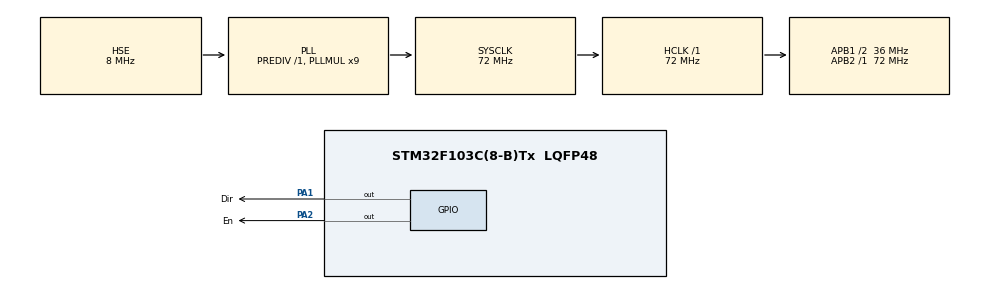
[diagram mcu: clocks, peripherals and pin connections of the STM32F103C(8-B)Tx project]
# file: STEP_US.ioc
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FREERTOS.Tasks01=defaultTask,0,128,StartDefaultTask,Default,NULL,Dynamic,NULL,NULL
Mcu.Family=STM32F1
Mcu.Name=STM32F103C(8-B)Tx
Mcu.Package=LQFP48
NVIC.PriorityGroup=NVIC_PRIORITYGROUP_4
PA1.GPIO_Label=Dir
PA1.Signal=GPIO_Output
PA13.Mode=Serial_Wire
PA13.Signal=SYS_JTMS-SWDIO
PA14.Mode=Serial_Wire
PA14.Signal=SYS_JTCK-SWCLK
PA2.GPIO_Label=En
PA2.Signal=GPIO_Output
PD0-OSC_IN.Mode=HSE-External-Oscillator
PD0-OSC_IN.Signal=RCC_OSC_IN
PD1-OSC_OUT.Mode=HSE-External-Oscillator
PD1-OSC_OUT.Signal=RCC_OSC_OUT
ProjectManager.HeapSize=0x200
ProjectManager.StackSize=0x400
ProjectManager.TargetToolchain=STM32CubeIDE
RCC.AHBFreq_Value=72000000
RCC.APB1CLKDivider=RCC_HCLK_DIV2
RCC.APB1Freq_Value=36000000
RCC.APB1TimFreq_Value=72000000
RCC.APB2Freq_Value=72000000
RCC.APB2TimFreq_Value=72000000
RCC.HCLKFreq_Value=72000000
RCC.PLLMUL=RCC_PLL_MUL9
RCC.PLLSourceVirtual=RCC_PLLSOURCE_HSE
RCC.SYSCLKFreq_VALUE=72000000
RCC.SYSCLKSource=RCC_SYSCLKSOURCE_PLLCLK
RCC.USBFreq_Value=72000000
TIM2.Prescaler=72-1
VP_FREERTOS_VS_CMSIS_V1.Mode=CMSIS_V1
VP_TIM2_VS_ClockSourceINT.Mode=Internal
board=custom

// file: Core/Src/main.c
/* USER CODE BEGIN Header */
/**
  ******************************************************************************
  * @file           : main.c
  * @brief          : Main program body
  ******************************************************************************
  * @attention
  *
  * Copyright (c) 2023 STMicroelectronics.
  * All rights reserved.
  *
  * This software is licensed under terms that can be found in the LICENSE file
  * in the root directory of this software component.
  * If no LICENSE file comes with this software, it is provided AS-IS.
  *
  ******************************************************************************
  */
/* USER CODE END Header */
#include "main.h"
#include "cmsis_os.h"

TIM_HandleTypeDef htim2;

osThreadId defaultTaskHandle;

void SystemClock_Config(void);
static void MX_GPIO_Init(void);
static void MX_TIM2_Init(void);
void StartDefaultTask(void const * argument);

/* USER CODE BEGIN 0 */
void Delayus(uint16_t us){
	__HAL_TIM_SET_COUNTER(&htim2,0);
		while(__HAL_TIM_GET_COUNTER(&htim2)<us);
}
/* USER CODE END 0 */

int main(void)
{

  /* MCU Configuration--------------------------------------------------------*/

  /* Reset of all peripherals, Initializes the Flash interface and the Systick. */
  HAL_Init();

  /* Configure the system clock */
  SystemClock_Config();

  /* Initialize all configured peripherals */
  MX_GPIO_Init();
  MX_TIM2_Init();

  /* Create the thread(s) */
  /* definition and creation of defaultTask */
  osThreadDef(defaultTask, StartDefaultTask, osPriorityNormal, 0, 128);
  defaultTaskHandle = osThreadCreate(osThread(defaultTask), NULL);

  /* Start scheduler */
  osKernelStart();

  /* We should never get here as control is now taken by the scheduler */
  /* Infinite loop */
  while (1)
  {

  }
}

void SystemClock_Config(void)
{
  RCC_OscInitTypeDef RCC_OscInitStruct = {0};
  RCC_ClkInitTypeDef RCC_ClkInitStruct = {0};

  /** Initializes the RCC Oscillators according to the specified parameters
  * in the RCC_OscInitTypeDef structure.
  */
  RCC_OscInitStruct.OscillatorType = RCC_OSCILLATORTYPE_HSE;
  RCC_OscInitStruct.HSEState = RCC_HSE_ON;
  RCC_OscInitStruct.HSEPredivValue = RCC_HSE_PREDIV_DIV1;
  RCC_OscInitStruct.HSIState = RCC_HSI_ON;
  RCC_OscInitStruct.PLL.PLLState = RCC_PLL_ON;
  RCC_OscInitStruct.PLL.PLLSource = RCC_PLLSOURCE_HSE;
  RCC_OscInitStruct.PLL.PLLMUL = RCC_PLL_MUL9;
  if (HAL_RCC_OscConfig(&RCC_OscInitStruct) != HAL_OK)
  {
    Error_Handler();
  }

  /** Initializes the CPU, AHB and APB buses clocks
  */
  RCC_ClkInitStruct.ClockType = RCC_CLOCKTYPE_HCLK|RCC_CLOCKTYPE_SYSCLK
                              |RCC_CLOCKTYPE_PCLK1|RCC_CLOCKTYPE_PCLK2;
  RCC_ClkInitStruct.SYSCLKSource = RCC_SYSCLKSOURCE_PLLCLK;
  RCC_ClkInitStruct.AHBCLKDivider = RCC_SYSCLK_DIV1;
  RCC_ClkInitStruct.APB1CLKDivider = RCC_HCLK_DIV2;
  RCC_ClkInitStruct.APB2CLKDivider = RCC_HCLK_DIV1;

  if (HAL_RCC_ClockConfig(&RCC_ClkInitStruct, FLASH_LATENCY_2) != HAL_OK)
  {
    Error_Handler();
  }
}

static void MX_TIM2_Init(void)
{

  TIM_ClockConfigTypeDef sClockSourceConfig = {0};
  TIM_MasterConfigTypeDef sMasterConfig = {0};

  htim2.Instance = TIM2;
  htim2.Init.Prescaler = 72-1;
  htim2.Init.CounterMode = TIM_COUNTERMODE_UP;
  htim2.Init.Period = 65535;
  htim2.Init.ClockDivision = TIM_CLOCKDIVISION_DIV1;
  htim2.Init.AutoReloadPreload = TIM_AUTORELOAD_PRELOAD_DISABLE;
  if (HAL_TIM_Base_Init(&htim2) != HAL_OK)
  {
    Error_Handler();
  }
  sClockSourceConfig.ClockSource = TIM_CLOCKSOURCE_INTERNAL;
  if (HAL_TIM_ConfigClockSource(&htim2, &sClockSourceConfig) != HAL_OK)
  {
    Error_Handler();
  }
  sMasterConfig.MasterOutputTrigger = TIM_TRGO_RESET;
  sMasterConfig.MasterSlaveMode = TIM_MASTERSLAVEMODE_DISABLE;
  if (HAL_TIMEx_MasterConfigSynchronization(&htim2, &sMasterConfig) != HAL_OK)
  {
    Error_Handler();
  }

}

static void MX_GPIO_Init(void)
{
  GPIO_InitTypeDef GPIO_InitStruct = {0};

  /* GPIO Ports Clock Enable */
  __HAL_RCC_GPIOD_CLK_ENABLE();
  __HAL_RCC_GPIOA_CLK_ENABLE();

  /*Configure GPIO pin Output Level */
  HAL_GPIO_WritePin(GPIOA, Dir_Pin|En_Pin, GPIO_PIN_RESET);

  /*Configure GPIO pins : Dir_Pin En_Pin */
  GPIO_InitStruct.Pin = Dir_Pin|En_Pin;
  GPIO_InitStruct.Mode = GPIO_MODE_OUTPUT_PP;
  GPIO_InitStruct.Pull = GPIO_NOPULL;
  GPIO_InitStruct.Speed = GPIO_SPEED_FREQ_LOW;
  HAL_GPIO_Init(GPIOA, &GPIO_InitStruct);

}

/* USER CODE BEGIN 4 */
int currentAngle; // goc hien tai
int numstep; //so buoc can di
int pre_angle;
double anglePerStep=1.8;//che do /1;
int angle;//goc can huong toi

void driveStep(){
	int n =0;
	if(currentAngle != angle){
		if( currentAngle < angle){
						HAL_GPIO_WritePin(Dir_GPIO_Port, Dir_Pin, 1);
						n = angle - currentAngle;
						numstep = n/anglePerStep *2;
					}
					else if( currentAngle > angle){
						HAL_GPIO_WritePin(Dir_GPIO_Port, Dir_Pin, 0);
						n = currentAngle - angle;
						if( angle == 0){
							n = currentAngle;
						}
						numstep = n/anglePerStep *2;
					}
					for(int x = 0; x < numstep; x++) {
						HAL_GPIO_WritePin(En_GPIO_Port, En_Pin, 1);
						osDelay(1);
						HAL_GPIO_WritePin(En_GPIO_Port, En_Pin, 0);
						osDelay(1);
					}

					currentAngle = angle;
	}
		}

//
//		if (HAL_GPIO_ReadPin(GPIOA, GPIO_PIN_8) == 1){
////				  home = 1;
//				  angle = intial_Rotate;
//				  currentAngle = intial_Rotate;
//			  }
////	vPos = 1;
/* USER CODE END 4 */

void StartDefaultTask(void const * argument)
{
  /* USER CODE BEGIN 5 */
  /* Infinite loop */
  for(;;)
  {
	  driveStep();
  }
  /* USER CODE END 5 */
}

void Error_Handler(void)
{
  __disable_irq();
  while (1)
  {
  }
}
